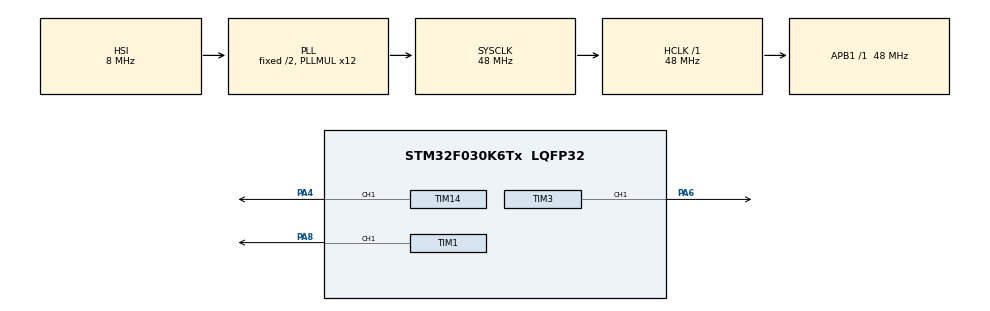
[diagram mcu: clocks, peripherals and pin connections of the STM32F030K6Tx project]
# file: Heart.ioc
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Mcu.Family=STM32F0
Mcu.Name=STM32F030K6Tx
Mcu.Package=LQFP32
PA13.Mode=Serial_Wire
PA13.Signal=SYS_SWDIO
PA14.Mode=Serial_Wire
PA14.Signal=SYS_SWCLK
PA4.Signal=S_TIM14_CH1
PA6.Signal=S_TIM3_CH1
PA8.Signal=S_TIM1_CH1
ProjectManager.HeapSize=0x200
ProjectManager.StackSize=0x400
ProjectManager.TargetToolchain=SW4STM32
RCC.AHBFreq_Value=48000000
RCC.APB1Freq_Value=48000000
RCC.APB1TimFreq_Value=48000000
RCC.HCLKFreq_Value=48000000
RCC.PLLMUL=RCC_PLL_MUL12
RCC.SYSCLKFreq_VALUE=48000000
RCC.SYSCLKSource=RCC_SYSCLKSOURCE_PLLCLK
SH.S_TIM14_CH1.0=TIM14_CH1,PWM Generation1 CH1
SH.S_TIM1_CH1.0=TIM1_CH1,PWM Generation1 CH1
SH.S_TIM3_CH1.0=TIM3_CH1,PWM Generation1 CH1
TIM1.Channel-PWM\ Generation1\ CH1=TIM_CHANNEL_1
TIM1.OCFastMode_PWM-PWM\ Generation1\ CH1=TIM_OCFAST_ENABLE
TIM1.Period=5000
TIM1.Pulse-PWM\ Generation1\ CH1=0
TIM14.Channel=TIM_CHANNEL_1
TIM14.OCFastMode_PWM=TIM_OCFAST_ENABLE
TIM14.Period=5000
TIM14.Pulse=0
TIM3.Channel-PWM\ Generation1\ CH1=TIM_CHANNEL_1
TIM3.OCFastMode_PWM-PWM\ Generation1\ CH1=TIM_OCFAST_ENABLE
TIM3.Period=5000
TIM3.Pulse-PWM\ Generation1\ CH1=0
VP_TIM14_VS_ClockSourceINT.Mode=Enable_Timer
VP_TIM1_VS_ClockSourceINT.Mode=Internal
VP_TIM3_VS_ClockSourceINT.Mode=Internal
board=custom

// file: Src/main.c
/* USER CODE BEGIN Header */
/**
  ******************************************************************************
  * @file           : main.c
  * @brief          : Main program body
  ******************************************************************************
  ** This notice applies to any and all portions of this file
  * that are not between comment pairs USER CODE BEGIN and
  * USER CODE END. Other portions of this file, whether
  * inserted by the user or by software development tools
  * are owned by their respective copyright owners.
  *
  * COPYRIGHT(c) 2019 STMicroelectronics
  *
  * Redistribution and use in source and binary forms, with or without modification,
  * are permitted provided that the following conditions are met:
  *   1. Redistributions of source code must retain the above copyright notice,
  *      this list of conditions and the following disclaimer.
  *   2. Redistributions in binary form must reproduce the above copyright notice,
  *      this list of conditions and the following disclaimer in the documentation
  *      and/or other materials provided with the distribution.
  *   3. Neither the name of STMicroelectronics nor the names of its contributors
  *      may be used to endorse or promote products derived from this software
  *      without specific prior written permission.
  *
  * THIS SOFTWARE IS PROVIDED BY THE COPYRIGHT HOLDERS AND CONTRIBUTORS "AS IS"
  * AND ANY EXPRESS OR IMPLIED WARRANTIES, INCLUDING, BUT NOT LIMITED TO, THE
  * IMPLIED WARRANTIES OF MERCHANTABILITY AND FITNESS FOR A PARTICULAR PURPOSE ARE
  * DISCLAIMED. IN NO EVENT SHALL THE COPYRIGHT HOLDER OR CONTRIBUTORS BE LIABLE
  * FOR ANY DIRECT, INDIRECT, INCIDENTAL, SPECIAL, EXEMPLARY, OR CONSEQUENTIAL
  * DAMAGES (INCLUDING, BUT NOT LIMITED TO, PROCUREMENT OF SUBSTITUTE GOODS OR
  * SERVICES; LOSS OF USE, DATA, OR PROFITS; OR BUSINESS INTERRUPTION) HOWEVER
  * CAUSED AND ON ANY THEORY OF LIABILITY, WHETHER IN CONTRACT, STRICT LIABILITY,
  * OR TORT (INCLUDING NEGLIGENCE OR OTHERWISE) ARISING IN ANY WAY OUT OF THE USE
  * OF THIS SOFTWARE, EVEN IF ADVISED OF THE POSSIBILITY OF SUCH DAMAGE.
  *
  ******************************************************************************
  */
/* USER CODE END Header */

#include "main.h"

TIM_HandleTypeDef htim1;
TIM_HandleTypeDef htim3;
TIM_HandleTypeDef htim14;

void SystemClock_Config(void);
static void MX_GPIO_Init(void);
static void MX_TIM1_Init(void);
static void MX_TIM3_Init(void);
static void MX_TIM14_Init(void);

int main(void)
{

  /* MCU Configuration--------------------------------------------------------*/

  /* Reset of all peripherals, Initializes the Flash interface and the Systick. */
  HAL_Init();

  /* Configure the system clock */
  SystemClock_Config();

  /* Initialize all configured peripherals */
  MX_GPIO_Init();
  MX_TIM1_Init();
  MX_TIM3_Init();
  MX_TIM14_Init();
  /* USER CODE BEGIN 2 */
  TIM1->CCR1 = 1;
  TIM3->CCR1 = 1;
  TIM14->CCR1 = 1;
  HAL_TIM_PWM_Start(&htim1, TIM_CHANNEL_1);
  HAL_TIM_PWM_Start(&htim3, TIM_CHANNEL_1);
  HAL_TIM_PWM_Start(&htim14, TIM_CHANNEL_1);
  /* USER CODE END 2 */

  /* Infinite loop */
  while (1)
  {

  }
}

void SystemClock_Config(void)
{
  RCC_OscInitTypeDef RCC_OscInitStruct = {0};
  RCC_ClkInitTypeDef RCC_ClkInitStruct = {0};

  /**Initializes the CPU, AHB and APB busses clocks
  */
  RCC_OscInitStruct.OscillatorType = RCC_OSCILLATORTYPE_HSI;
  RCC_OscInitStruct.HSIState = RCC_HSI_ON;
  RCC_OscInitStruct.HSICalibrationValue = RCC_HSICALIBRATION_DEFAULT;
  RCC_OscInitStruct.PLL.PLLState = RCC_PLL_ON;
  RCC_OscInitStruct.PLL.PLLSource = RCC_PLLSOURCE_HSI;
  RCC_OscInitStruct.PLL.PLLMUL = RCC_PLL_MUL12;
  RCC_OscInitStruct.PLL.PREDIV = RCC_PREDIV_DIV1;
  if (HAL_RCC_OscConfig(&RCC_OscInitStruct) != HAL_OK)
  {
    Error_Handler();
  }
  /**Initializes the CPU, AHB and APB busses clocks
  */
  RCC_ClkInitStruct.ClockType = RCC_CLOCKTYPE_HCLK|RCC_CLOCKTYPE_SYSCLK
                              |RCC_CLOCKTYPE_PCLK1;
  RCC_ClkInitStruct.SYSCLKSource = RCC_SYSCLKSOURCE_PLLCLK;
  RCC_ClkInitStruct.AHBCLKDivider = RCC_SYSCLK_DIV1;
  RCC_ClkInitStruct.APB1CLKDivider = RCC_HCLK_DIV1;

  if (HAL_RCC_ClockConfig(&RCC_ClkInitStruct, FLASH_LATENCY_1) != HAL_OK)
  {
    Error_Handler();
  }
}

static void MX_TIM1_Init(void)
{

  TIM_ClockConfigTypeDef sClockSourceConfig = {0};
  TIM_MasterConfigTypeDef sMasterConfig = {0};
  TIM_OC_InitTypeDef sConfigOC = {0};
  TIM_BreakDeadTimeConfigTypeDef sBreakDeadTimeConfig = {0};

  htim1.Instance = TIM1;
  htim1.Init.Prescaler = 0;
  htim1.Init.CounterMode = TIM_COUNTERMODE_UP;
  htim1.Init.Period = 5000;
  htim1.Init.ClockDivision = TIM_CLOCKDIVISION_DIV1;
  htim1.Init.RepetitionCounter = 0;
  htim1.Init.AutoReloadPreload = TIM_AUTORELOAD_PRELOAD_DISABLE;
  if (HAL_TIM_Base_Init(&htim1) != HAL_OK)
  {
    Error_Handler();
  }
  sClockSourceConfig.ClockSource = TIM_CLOCKSOURCE_INTERNAL;
  if (HAL_TIM_ConfigClockSource(&htim1, &sClockSourceConfig) != HAL_OK)
  {
    Error_Handler();
  }
  if (HAL_TIM_PWM_Init(&htim1) != HAL_OK)
  {
    Error_Handler();
  }
  sMasterConfig.MasterOutputTrigger = TIM_TRGO_RESET;
  sMasterConfig.MasterSlaveMode = TIM_MASTERSLAVEMODE_DISABLE;
  if (HAL_TIMEx_MasterConfigSynchronization(&htim1, &sMasterConfig) != HAL_OK)
  {
    Error_Handler();
  }
  sConfigOC.OCMode = TIM_OCMODE_PWM1;
  sConfigOC.Pulse = 0;
  sConfigOC.OCPolarity = TIM_OCPOLARITY_HIGH;
  sConfigOC.OCNPolarity = TIM_OCNPOLARITY_HIGH;
  sConfigOC.OCFastMode = TIM_OCFAST_ENABLE;
  sConfigOC.OCIdleState = TIM_OCIDLESTATE_RESET;
  sConfigOC.OCNIdleState = TIM_OCNIDLESTATE_RESET;
  if (HAL_TIM_PWM_ConfigChannel(&htim1, &sConfigOC, TIM_CHANNEL_1) != HAL_OK)
  {
    Error_Handler();
  }
  sBreakDeadTimeConfig.OffStateRunMode = TIM_OSSR_DISABLE;
  sBreakDeadTimeConfig.OffStateIDLEMode = TIM_OSSI_DISABLE;
  sBreakDeadTimeConfig.LockLevel = TIM_LOCKLEVEL_OFF;
  sBreakDeadTimeConfig.DeadTime = 0;
  sBreakDeadTimeConfig.BreakState = TIM_BREAK_DISABLE;
  sBreakDeadTimeConfig.BreakPolarity = TIM_BREAKPOLARITY_HIGH;
  sBreakDeadTimeConfig.AutomaticOutput = TIM_AUTOMATICOUTPUT_DISABLE;
  if (HAL_TIMEx_ConfigBreakDeadTime(&htim1, &sBreakDeadTimeConfig) != HAL_OK)
  {
    Error_Handler();
  }
  HAL_TIM_MspPostInit(&htim1);

}

static void MX_TIM3_Init(void)
{

  TIM_ClockConfigTypeDef sClockSourceConfig = {0};
  TIM_MasterConfigTypeDef sMasterConfig = {0};
  TIM_OC_InitTypeDef sConfigOC = {0};

  htim3.Instance = TIM3;
  htim3.Init.Prescaler = 0;
  htim3.Init.CounterMode = TIM_COUNTERMODE_UP;
  htim3.Init.Period = 5000;
  htim3.Init.ClockDivision = TIM_CLOCKDIVISION_DIV1;
  htim3.Init.AutoReloadPreload = TIM_AUTORELOAD_PRELOAD_DISABLE;
  if (HAL_TIM_Base_Init(&htim3) != HAL_OK)
  {
    Error_Handler();
  }
  sClockSourceConfig.ClockSource = TIM_CLOCKSOURCE_INTERNAL;
  if (HAL_TIM_ConfigClockSource(&htim3, &sClockSourceConfig) != HAL_OK)
  {
    Error_Handler();
  }
  if (HAL_TIM_PWM_Init(&htim3) != HAL_OK)
  {
    Error_Handler();
  }
  sMasterConfig.MasterOutputTrigger = TIM_TRGO_RESET;
  sMasterConfig.MasterSlaveMode = TIM_MASTERSLAVEMODE_DISABLE;
  if (HAL_TIMEx_MasterConfigSynchronization(&htim3, &sMasterConfig) != HAL_OK)
  {
    Error_Handler();
  }
  sConfigOC.OCMode = TIM_OCMODE_PWM1;
  sConfigOC.Pulse = 0;
  sConfigOC.OCPolarity = TIM_OCPOLARITY_HIGH;
  sConfigOC.OCFastMode = TIM_OCFAST_ENABLE;
  if (HAL_TIM_PWM_ConfigChannel(&htim3, &sConfigOC, TIM_CHANNEL_1) != HAL_OK)
  {
    Error_Handler();
  }
  HAL_TIM_MspPostInit(&htim3);

}

static void MX_TIM14_Init(void)
{

  TIM_OC_InitTypeDef sConfigOC = {0};

  htim14.Instance = TIM14;
  htim14.Init.Prescaler = 0;
  htim14.Init.CounterMode = TIM_COUNTERMODE_UP;
  htim14.Init.Period = 5000;
  htim14.Init.ClockDivision = TIM_CLOCKDIVISION_DIV1;
  htim14.Init.AutoReloadPreload = TIM_AUTORELOAD_PRELOAD_DISABLE;
  if (HAL_TIM_Base_Init(&htim14) != HAL_OK)
  {
    Error_Handler();
  }
  if (HAL_TIM_PWM_Init(&htim14) != HAL_OK)
  {
    Error_Handler();
  }
  sConfigOC.OCMode = TIM_OCMODE_PWM1;
  sConfigOC.Pulse = 0;
  sConfigOC.OCPolarity = TIM_OCPOLARITY_HIGH;
  sConfigOC.OCFastMode = TIM_OCFAST_ENABLE;
  if (HAL_TIM_PWM_ConfigChannel(&htim14, &sConfigOC, TIM_CHANNEL_1) != HAL_OK)
  {
    Error_Handler();
  }
  HAL_TIM_MspPostInit(&htim14);

}

static void MX_GPIO_Init(void)
{

  /* GPIO Ports Clock Enable */
  __HAL_RCC_GPIOA_CLK_ENABLE();

}

void Error_Handler(void)
{
}

/************************ (C) COPYRIGHT STMicroelectronics *****END OF FILE****/
